AUTOSAR XML (schema 314)
package /ComponentType
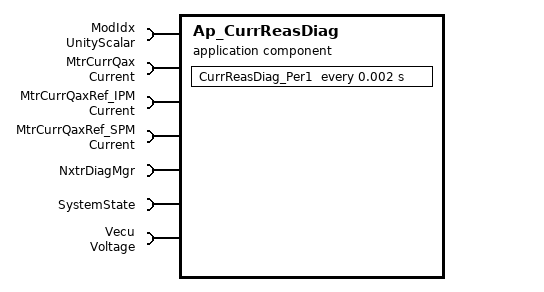
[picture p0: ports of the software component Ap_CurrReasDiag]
  application software component type Ap_CurrReasDiag  # PI Current Control
    7 x require port:
      ModIdx: unqueued-receiver-com-spec{data-element=Uls_f32, init-value=D_ZERO_ULS_F32}, required-interface=UnityScalar
      MtrCurrQax: unqueued-receiver-com-spec{data-element=Amp_f32, init-value=D_ZERO_ULS_F32}, required-interface=Current
      MtrCurrQaxRef_IPM: unqueued-receiver-com-spec{data-element=Amp_f32, init-value=D_ZERO_ULS_F32}, required-interface=Current
      MtrCurrQaxRef_SPM: unqueued-receiver-com-spec{data-element=Amp_f32, init-value=D_ZERO_ULS_F32}, required-interface=Current
      NxtrDiagMgr: required-com-specs=[GetNTCFailed, GetNTCStatus, ResetEventStatus, SetNTCStatus, SetOperationCycleState], required-interface=NxtrDiagMgr
      SystemState: required-interface=SystemState
      Vecu: unqueued-receiver-com-spec{data-element=Volt_f32, init-value=D_VECUMIN_VOLTS_F32}, required-interface=Voltage
  internal behavior Ap_CurrReasDiag_InternalBehavior: component=Ap_CurrReasDiag
    timing event TMT_CurrReasDiag_Per1: mode-dependency=dependent-on-mode=[SystemState.Mode.DISABLE, SystemState.Mode.OFF, SystemState.Mode.WARMINIT], start-on-event=CurrReasDiag_Per1, period=0.002
    port-api-options:
      enable-take-address=false, indirect-api=false, port=ModIdx
      enable-take-address=false, indirect-api=false, port=MtrCurrQax
      enable-take-address=false, indirect-api=false, port=MtrCurrQaxRef_IPM
      enable-take-address=false, indirect-api=false, port=MtrCurrQaxRef_SPM
      enable-take-address=false, indirect-api=false, port=NxtrDiagMgr
      enable-take-address=false, indirect-api=false, port=SystemState
      enable-take-address=false, indirect-api=false, port=Vecu
    runnable CurrReasDiag_Per1
      5 x data read access:
        READ_ModIdx_Uls_f32: data-element=ModIdx.Uls_f32
        READ_MtrCurrQax_Amp_f32: data-element=MtrCurrQax.Amp_f32
        READ_MtrCurrQaxRef_IPM_Amp_f32: data-element=MtrCurrQaxRef_IPM.Amp_f32
        READ_MtrCurrQaxRef_SPM_Amp_f32: data-element=MtrCurrQaxRef_SPM.Amp_f32
        READ_Vecu_Volt_f32: data-element=Vecu.Volt_f32
      sync call SC_NxtrDiagMgr_SetNTCStatus: operation=NxtrDiagMgr.SetNTCStatus, timeout=0
  swc implementation Ap_CurrReasDiag_Implementation: behavior=Ap_CurrReasDiag_InternalBehavior
    code-descriptors:
      code Code: type=SRC
